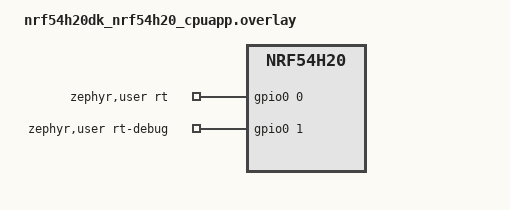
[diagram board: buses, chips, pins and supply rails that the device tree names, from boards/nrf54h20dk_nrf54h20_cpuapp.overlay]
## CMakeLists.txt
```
#
# Copyright (c) 2026 Nordic Semiconductor
#
# SPDX-License-Identifier: LicenseRef-Nordic-5-Clause
#

cmake_minimum_required(VERSION 3.20.0)
find_package(Zephyr REQUIRED HINTS $ENV{ZEPHYR_BASE})
project(rtfw_timer_gpio)

target_sources(app PRIVATE
  src/main.c
  src/timer_control.c
  src/timer_fastpath.c
)
```

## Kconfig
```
#
# Copyright (c) 2026 Nordic Semiconductor
#
# SPDX-License-Identifier: LicenseRef-Nordic-5-Clause
#

mainmenu "RTFW timer/GPIO backend"

config SAMPLE_RTFW_IRQ_PRIORITY
	int "TIMER zero-latency IRQ priority"
	default 1 if SOC_SERIES_NRF54L
	default 0
	range 0 7
	help
	  Select the priority of the sample-owned TIMER source interrupt.
	  nRF54L uses priority 1 so MPSL priority 0 can preempt it, while
	  nRF54H20 uses priority 0 because the radio runs on another core.

config SAMPLE_RTFW_TIMER_MIN_PERIOD_US
	int "Minimum accepted timer period (us)"
	default 10
	range 2 2147483647
	help
	  Set the shortest period accepted by the sample API. The TIMER runs at
	  1 MHz and requires at least two counter ticks. Values below this
	  limit are rejected instead of being silently rounded by the
	  zero-latency command handler.

config SAMPLE_RTFW_TIMER_MAX_PERIOD_US
	int "Maximum accepted timer period (us)"
	default 1000000
	range 2 2147483647
	help
	  Set the longest period accepted by the sample API. This value must be
	  greater than or equal to the configured minimum period. The default
	  sample period must remain within the resulting accepted range or the
	  build is rejected.

config SAMPLE_RTFW_TIMER_TELEMETRY_DECIMATION
	int "Emit one tick event every N timer events (0 disables)"
	default 0
	range 0 1000000
	help
	  Tick telemetry is disabled by default. Configuration changes remain
	  event-on-change and are not affected by this setting.

config SAMPLE_RTFW_ISR_TEST_LOAD
	bool "Inject a controlled busy loop into the TIMER fast path"
	help
	  Add a bounded NOP loop to the source ISR for stress and
	  coexistence measurements. The configured iteration count is
	  executed after the registered fast-path callback. Keep this
	  option disabled for baseline latency measurements.

config SAMPLE_RTFW_ISR_TEST_LOAD_CYCLES
	int "NOP iterations in the injected ISR load"
	depends on SAMPLE_RTFW_ISR_TEST_LOAD
	default 100
	range 1 1000000

config SAMPLE_RTFW_DEBUG_PIN
	bool "Expose TIMER ISR execution time on a debug pin"
	help
	  Drive the board-specific debug pin while the direct source ISR
	  executes so its latency and duration can be measured with a
	  logic analyzer. The output includes framework command handling
	  and the registered sample fast-path callback.

source "Kconfig.zephyr"
```

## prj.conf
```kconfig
#
# Copyright (c) 2026 Nordic Semiconductor
#
# SPDX-License-Identifier: LicenseRef-Nordic-5-Clause
#

CONFIG_NCS_SAMPLES_DEFAULTS=y
CONFIG_RTFW=y
CONFIG_RTFW_COMMAND_DATA_SIZE=8
CONFIG_ZERO_LATENCY_IRQS=y
CONFIG_ZERO_LATENCY_LEVELS=2

CONFIG_DK_LIBRARY=y

CONFIG_SHELL=y
CONFIG_SYSTEM_WORKQUEUE_STACK_SIZE=2048
```

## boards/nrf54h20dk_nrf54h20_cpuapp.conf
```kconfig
CONFIG_BT=n
CONFIG_ZERO_LATENCY_LEVELS=1
CONFIG_SAMPLE_RTFW_IRQ_PRIORITY=0
```

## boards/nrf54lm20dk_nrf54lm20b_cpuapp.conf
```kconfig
CONFIG_BT=y
CONFIG_BT_PERIPHERAL=y
CONFIG_BT_DEVICE_NAME="Nordic_RTFW_Timer"
CONFIG_BT_LBS=y
CONFIG_SAMPLE_RTFW_IRQ_PRIORITY=1
```

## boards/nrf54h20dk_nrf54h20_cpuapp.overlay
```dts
/*
 * Copyright (c) 2026 Nordic Semiconductor
 *
 * SPDX-License-Identifier: LicenseRef-Nordic-5-Clause
 */

#include <zephyr/dt-bindings/gpio/gpio.h>

/ {
	aliases {
		rt-timer = &timer130;
		rt-egu = &egu130;
	};

	zephyr,user {
		rt-gpios = <&gpio0 0 GPIO_ACTIVE_HIGH>;
		rt-debug-gpios = <&gpio0 1 GPIO_ACTIVE_HIGH>;
	};
};

&timer130 {
	status = "reserved";
};

&egu130 {
	status = "reserved";
};

&gpio0 {
	status = "okay";
};
```

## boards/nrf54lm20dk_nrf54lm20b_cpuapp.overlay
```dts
/*
 * Copyright (c) 2026 Nordic Semiconductor
 *
 * SPDX-License-Identifier: LicenseRef-Nordic-5-Clause
 */

#include <zephyr/dt-bindings/gpio/gpio.h>

/ {
	aliases {
		rt-timer = &timer20;
		rt-egu = &egu20;
	};

	zephyr,user {
		rt-gpios = <&gpio1 4 GPIO_ACTIVE_HIGH>;
		rt-debug-gpios = <&gpio1 5 GPIO_ACTIVE_HIGH>;
	};
};

&timer20 {
	status = "disabled";
};

&egu20 {
	status = "disabled";
};
```

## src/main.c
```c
/*
 * Copyright (c) 2026 Nordic Semiconductor
 *
 * SPDX-License-Identifier: LicenseRef-Nordic-5-Clause
 */

#include <errno.h>
#include <zephyr/kernel.h>
#include <zephyr/shell/shell.h>
#include <zephyr/sys/printk.h>
#include <dk_buttons_and_leds.h>

#if defined(CONFIG_BT)
#include <zephyr/bluetooth/bluetooth.h>
#include <zephyr/bluetooth/conn.h>
#include <zephyr/bluetooth/gatt.h>
#include <zephyr/bluetooth/hci.h>
#include <zephyr/bluetooth/uuid.h>
#include <bluetooth/services/lbs.h>
#endif

#include "timer_internal.h"

#define RUN_STATUS_LED         DK_LED1
#define CONNECTION_STATUS_LED  DK_LED2
#define EVENT_STATUS_LED       DK_LED3
#define RUN_LED_INTERVAL_MS    1000

#if defined(CONFIG_BT)
#define DEVICE_NAME     CONFIG_BT_DEVICE_NAME
#define DEVICE_NAME_LEN (sizeof(DEVICE_NAME) - 1)

static struct k_work advertising_work;

static const struct bt_data advertising_data[] = {
	BT_DATA_BYTES(BT_DATA_FLAGS, BT_LE_AD_GENERAL | BT_LE_AD_NO_BREDR),
	BT_DATA(BT_DATA_NAME_COMPLETE, DEVICE_NAME, DEVICE_NAME_LEN),
};

static const struct bt_data scan_data[] = {
	BT_DATA_BYTES(BT_DATA_UUID128_ALL, BT_UUID_LBS_VAL),
};

static void advertising_handler(struct k_work *work)
{
	int error;

	ARG_UNUSED(work);
	error = bt_le_adv_start(BT_LE_ADV_CONN_FAST_2, advertising_data,
				ARRAY_SIZE(advertising_data), scan_data,
				ARRAY_SIZE(scan_data));
	printk("Advertising start: %d\n", error);
}

static void connected(struct bt_conn *connection, uint8_t error)
{
	ARG_UNUSED(connection);
	if (error == 0U) {
		dk_set_led_on(CONNECTION_STATUS_LED);
	}
}

static void disconnected(struct bt_conn *connection, uint8_t reason)
{
	ARG_UNUSED(connection);
	ARG_UNUSED(reason);
	dk_set_led_off(CONNECTION_STATUS_LED);
}

static void recycled(void)
{
	k_work_submit(&advertising_work);
}

BT_CONN_CB_DEFINE(connection_callbacks) = {
	.connected = connected,
	.disconnected = disconnected,
	.recycled = recycled,
};

static struct bt_lbs_cb lbs_callbacks;
#endif

static bool event_led_state;

static void event_handler(const struct rtfw_event *event, void *user_data)
{
	ARG_UNUSED(user_data);

	if (event->type == RTFW_EVENT_COMMAND_PROCESSED ||
	    event->type == RTFW_TIMER_EVENT_TICK) {
		event_led_state = !event_led_state;
		dk_set_led(EVENT_STATUS_LED, event_led_state);
	}
}

static int command_start(const struct shell *shell, size_t argc, char **argv)
{
	ARG_UNUSED(argc);
	ARG_UNUSED(argv);
	int error = rtfw_timer_enable(true);

	shell_print(shell, "RTFW timer start requested (%d)", error);
	return error;
}

static int command_stop(const struct shell *shell, size_t argc, char **argv)
{
	ARG_UNUSED(argc);
	ARG_UNUSED(argv);
	int error = rtfw_timer_enable(false);

	shell_print(shell, "RTFW timer stop requested (%d)", error);
	return error;
}

static int command_period(const struct shell *shell, size_t argc, char **argv)
{
	int parse_error = 0;
	unsigned long period_us;
	int error;

	ARG_UNUSED(argc);
	period_us = shell_strtoul(argv[1], 0, &parse_error);
	if (parse_error != 0 ||
	    period_us > CONFIG_SAMPLE_RTFW_TIMER_MAX_PERIOD_US) {
		shell_error(shell, "Invalid period '%s'", argv[1]);
		return -EINVAL;
	}

	error = rtfw_timer_period_set((uint32_t)period_us);
	if (error != 0) {
		shell_error(shell, "Allowed range: %u..%u us",
			    CONFIG_SAMPLE_RTFW_TIMER_MIN_PERIOD_US,
			    CONFIG_SAMPLE_RTFW_TIMER_MAX_PERIOD_US);
		return error;
	}

	shell_print(shell, "RTFW timer period requested: %lu us", period_us);
	return 0;
}

static int command_status(const struct shell *shell, size_t argc, char **argv)
{
	struct rtfw_timer_status status;
	int error;

	ARG_UNUSED(argc);
	ARG_UNUSED(argv);
	error = rtfw_timer_status_get(&status);
	if (error != 0) {
		return error;
	}

	shell_print(shell, "applied   : %s, %u us (%u ticks)",
		    status.enabled ? "running" : "stopped",
		    status.period_us, status.period_ticks);
	shell_print(shell, "requested : %s, %u us (%u ticks)",
		    status.requested_enabled ? "running" : "stopped",
		    status.requested_period_us, status.requested_period_ticks);
	shell_print(shell, "pending=%s ticks=%u dropped=%u max_depth=%u faults=0x%x",
		    status.pending ? "yes" : "no", status.tick_count,
		    status.dropped_events, status.max_queue_depth, status.faults);
	return 0;
}

SHELL_STATIC_SUBCMD_SET_CREATE(rtfw_commands,
	SHELL_CMD(start, NULL, "Start the TIMER/GPIO backend", command_start),
	SHELL_CMD(stop, NULL, "Stop the TIMER/GPIO backend", command_stop),
	SHELL_CMD_ARG(period, NULL, "Set period in microseconds", command_period, 2, 0),
	SHELL_CMD(status, NULL, "Show coherent backend status", command_status),
	SHELL_SUBCMD_SET_END
);
SHELL_CMD_REGISTER(rtfw, &rtfw_commands, "RTFW timer/GPIO control", NULL);

int main(void)
{
	int error;
	bool led = false;

	printk("Starting event-driven RTFW timer/GPIO backend\n");
	error = dk_leds_init();
	if (error != 0) {
		return error;
	}

	error = rtfw_timer_init(event_handler, NULL);
	if (error != 0) {
		printk("RTFW initialization failed: %d\n", error);
		return error;
	}
#if defined(CONFIG_BT)
	error = bt_enable(NULL);
	if (error != 0) {
		return error;
	}
	error = bt_lbs_init(&lbs_callbacks);
	if (error != 0) {
		return error;
	}
	k_work_init(&advertising_work, advertising_handler);
	k_work_submit(&advertising_work);
#endif
	printk("RTFW timer/GPIO backend initialized\n");

	for (;;) {
		led = !led;
		dk_set_led(RUN_STATUS_LED, led);
		k_sleep(K_MSEC(RUN_LED_INTERVAL_MS));
	}
}
```

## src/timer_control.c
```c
/*
 * Copyright (c) 2026 Nordic Semiconductor
 *
 * SPDX-License-Identifier: LicenseRef-Nordic-5-Clause
 */

#include <errno.h>
#include <string.h>
#include <zephyr/kernel.h>

#include "timer_internal.h"

static K_MUTEX_DEFINE(timer_lock);
static struct rtfw_timer_config desired_config;
static uint32_t desired_period_us;

static int config_publish(const struct rtfw_timer_config *config)
{
	struct rtfw_command command = {
		.id = RTFW_TIMER_COMMAND_CONFIGURE,
		.data_len = sizeof(*config),
	};

	memcpy(command.data, config, sizeof(*config));
	return rtfw_submit(&command);
}

int rtfw_timer_init(rtfw_event_cb_t event_handler, void *user_data)
{
	const struct rtfw_config framework_config = {
		.command_handler = rtfw_timer_command_handler,
		.fastpath_handler = rtfw_timer_fastpath_handler,
		.pend_source_irq = rtfw_timer_pend_source_irq,
		.event_handler = event_handler,
		.event_user_data = user_data,
	};
	int error;

	desired_period_us = RTFW_TIMER_DEFAULT_PERIOD_US;
	desired_config.enabled = 0U;
	desired_config.period_ticks =
		rtfw_timer_us_to_ticks(RTFW_TIMER_DEFAULT_PERIOD_US);

	error = rtfw_init(&framework_config);
	if (error != 0) {
		return error;
	}

	rtfw_timer_fastpath_init(desired_config.period_ticks);
	return config_publish(&desired_config);
}

int rtfw_timer_enable(bool enable)
{
	struct rtfw_timer_config config;
	int error;

	k_mutex_lock(&timer_lock, K_FOREVER);
	config = desired_config;
	config.enabled = enable ? 1U : 0U;
	error = config_publish(&config);
	if (error == 0) {
		desired_config = config;
	}
	k_mutex_unlock(&timer_lock);
	return error;
}

int rtfw_timer_period_set(uint32_t period_us)
{
	struct rtfw_timer_config config;
	uint32_t period_ticks;
	int error;

	if (period_us < CONFIG_SAMPLE_RTFW_TIMER_MIN_PERIOD_US ||
	    period_us > CONFIG_SAMPLE_RTFW_TIMER_MAX_PERIOD_US) {
		return -EINVAL;
	}
	period_ticks = rtfw_timer_us_to_ticks(period_us);
	if (period_ticks < RTFW_TIMER_MIN_PERIOD_TICKS) {
		return -EINVAL;
	}

	k_mutex_lock(&timer_lock, K_FOREVER);
	config = desired_config;
	config.period_ticks = period_ticks;
	error = config_publish(&config);
	if (error == 0) {
		desired_config = config;
		desired_period_us = period_us;
	}
	k_mutex_unlock(&timer_lock);
	return error;
}

int rtfw_timer_status_get(struct rtfw_timer_status *status)
{
	struct rtfw_status framework_status;
	struct rtfw_timer_config applied = {0};
	bool applied_valid;
	int error;

	if (status == NULL) {
		return -EINVAL;
	}

	k_mutex_lock(&timer_lock, K_FOREVER);
	error = rtfw_get_status(&framework_status);
	if (error != 0) {
		k_mutex_unlock(&timer_lock);
		return error;
	}

	status->requested_enabled = desired_config.enabled != 0U;
	status->requested_period_us = desired_period_us;
	status->requested_period_ticks = desired_config.period_ticks;

	applied_valid =
		framework_status.applied.id == RTFW_TIMER_COMMAND_CONFIGURE &&
		framework_status.applied.data_len == sizeof(applied);
	if (applied_valid) {
		memcpy(&applied, framework_status.applied.data,
		       sizeof(applied));
	}
	status->enabled =
		applied_valid && applied.enabled != 0U;
	status->period_ticks = applied_valid ? applied.period_ticks :
					      desired_config.period_ticks;
	status->period_us = rtfw_timer_ticks_to_us(status->period_ticks);
	status->pending = framework_status.pending;
	status->tick_count = rtfw_timer_tick_count_get();
	status->dropped_events = framework_status.dropped_events;
	status->max_queue_depth = framework_status.max_queue_depth;
	status->faults = framework_status.faults;
	k_mutex_unlock(&timer_lock);
	return 0;
}
```

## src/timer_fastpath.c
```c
/*
 * Copyright (c) 2026 Nordic Semiconductor
 *
 * SPDX-License-Identifier: LicenseRef-Nordic-5-Clause
 */

#include <errno.h>
#include <limits.h>
#include <string.h>
#include <cmsis_core.h>
#include <zephyr/irq.h>
#include <hal/nrf_gpio.h>
#include <hal/nrf_timer.h>

#include "timer_internal.h"
#include "timer_platform.h"

#define TIMER_TARGET_HZ 1000000U

static struct rtfw_timer_config applied_config;
static uint8_t timer_prescaler;
static uint32_t timer_hz;
static uint32_t tick_count;

static void timer_clock_resolve(void)
{
	uint32_t base_hz;
	uint8_t prescaler = 0U;

	if (timer_hz != 0U) {
		return;
	}

	base_hz = NRF_TIMER_BASE_FREQUENCY_GET(RTFW_TIMER);
	while (((base_hz >> prescaler) > TIMER_TARGET_HZ) && (prescaler < 9U)) {
		prescaler++;
	}

	timer_prescaler = prescaler;
	timer_hz = base_hz >> prescaler;
}

int rtfw_timer_command_handler(const struct rtfw_command *command,
			       void *user_data)
{
	struct rtfw_timer_config config;
	uint32_t ticks;

	ARG_UNUSED(user_data);
	if (command->id != RTFW_TIMER_COMMAND_CONFIGURE ||
	    command->data_len != sizeof(struct rtfw_timer_config)) {
		return -EINVAL;
	}

	memcpy(&config, command->data, sizeof(config));
	if (config.period_ticks < RTFW_TIMER_MIN_PERIOD_TICKS) {
		return -EINVAL;
	}
	ticks = config.period_ticks;

	/*
	 * A reconfiguration intentionally starts a new phase. STOP/CLEAR before
	 * changing CC0 prevents a smaller compare value from being stranded below
	 * the current counter until the 32-bit counter wraps.
	 */
	nrf_timer_task_trigger(RTFW_TIMER, NRF_TIMER_TASK_STOP);
	nrf_timer_task_trigger(RTFW_TIMER, NRF_TIMER_TASK_CLEAR);
	nrf_timer_event_clear(RTFW_TIMER, NRF_TIMER_EVENT_COMPARE0);
	nrf_timer_cc_set(RTFW_TIMER, NRF_TIMER_CC_CHANNEL0, ticks);

	applied_config.enabled = config.enabled != 0U;
	applied_config.period_ticks = ticks;
	if (applied_config.enabled != 0U) {
		nrf_timer_task_trigger(RTFW_TIMER, NRF_TIMER_TASK_START);
	} else {
		nrf_gpio_pin_clear(RTFW_GPIO_ABS);
	}

	return 0;
}

void rtfw_timer_pend_source_irq(void *user_data)
{
	ARG_UNUSED(user_data);
	NVIC_SetPendingIRQ(RTFW_TIMER_IRQN);
}

void rtfw_timer_fastpath_handler(void *user_data)
{
	bool timer_event =
		nrf_timer_event_check(RTFW_TIMER, NRF_TIMER_EVENT_COMPARE0);

	ARG_UNUSED(user_data);
	if (timer_event) {
		nrf_timer_event_clear(RTFW_TIMER, NRF_TIMER_EVENT_COMPARE0);
	}

	if (timer_event && applied_config.enabled != 0U) {
		struct rtfw_event event;
		uint32_t current_tick;

		nrf_gpio_pin_toggle(RTFW_GPIO_ABS);
		current_tick = __atomic_add_fetch(&tick_count, 1U, __ATOMIC_RELAXED);

#if CONFIG_SAMPLE_RTFW_TIMER_TELEMETRY_DECIMATION > 0
		if ((current_tick %
		     CONFIG_SAMPLE_RTFW_TIMER_TELEMETRY_DECIMATION) == 0U) {
			event.type = RTFW_TIMER_EVENT_TICK;
			event.value = current_tick;
			event.timestamp = current_tick;
			(void)rtfw_event_push(&event);
		}
#else
		(void)event;
#endif
	}
}

ISR_DIRECT_DECLARE(rtfw_timer_isr)
{
#if defined(CONFIG_SAMPLE_RTFW_DEBUG_PIN)
	nrf_gpio_pin_set(RTFW_DEBUG_GPIO_ABS);
#endif

	rtfw_fastpath_run();

#if defined(CONFIG_SAMPLE_RTFW_ISR_TEST_LOAD)
	for (uint32_t i = 0U;
	     i < CONFIG_SAMPLE_RTFW_ISR_TEST_LOAD_CYCLES; i++) {
		__NOP();
	}
#endif

#if defined(CONFIG_SAMPLE_RTFW_DEBUG_PIN)
	nrf_gpio_pin_clear(RTFW_DEBUG_GPIO_ABS);
#endif

	return 0;
}

uint32_t rtfw_timer_us_to_ticks(uint32_t microseconds)
{
	uint64_t ticks;

	timer_clock_resolve();
	ticks = ((uint64_t)microseconds * timer_hz) / 1000000ULL;
	return (uint32_t)MIN(ticks, UINT32_MAX);
}

uint32_t rtfw_timer_ticks_to_us(uint32_t ticks)
{
	uint64_t microseconds;

	timer_clock_resolve();
	microseconds = ((uint64_t)ticks * 1000000ULL) / timer_hz;
	return (uint32_t)MIN(microseconds, UINT32_MAX);
}

uint32_t rtfw_timer_tick_count_get(void)
{
	return __atomic_load_n(&tick_count, __ATOMIC_RELAXED);
}

void rtfw_timer_fastpath_init(uint32_t initial_period_ticks)
{
	timer_clock_resolve();
	applied_config.enabled = 0U;
	applied_config.period_ticks = initial_period_ticks;
	__atomic_store_n(&tick_count, 0U, __ATOMIC_RELAXED);

	nrf_gpio_cfg_output(RTFW_GPIO_ABS);
	nrf_gpio_pin_clear(RTFW_GPIO_ABS);
#if defined(CONFIG_SAMPLE_RTFW_DEBUG_PIN)
	nrf_gpio_cfg_output(RTFW_DEBUG_GPIO_ABS);
	nrf_gpio_pin_clear(RTFW_DEBUG_GPIO_ABS);
#endif

	nrf_timer_task_trigger(RTFW_TIMER, NRF_TIMER_TASK_STOP);
	nrf_timer_task_trigger(RTFW_TIMER, NRF_TIMER_TASK_CLEAR);
	nrf_timer_mode_set(RTFW_TIMER, NRF_TIMER_MODE_TIMER);
	nrf_timer_bit_width_set(RTFW_TIMER, NRF_TIMER_BIT_WIDTH_32);
	nrf_timer_prescaler_set(RTFW_TIMER, timer_prescaler);
	nrf_timer_cc_set(RTFW_TIMER, NRF_TIMER_CC_CHANNEL0, initial_period_ticks);
	nrf_timer_shorts_enable(RTFW_TIMER, NRF_TIMER_SHORT_COMPARE0_CLEAR_MASK);
	nrf_timer_event_clear(RTFW_TIMER, NRF_TIMER_EVENT_COMPARE0);
	nrf_timer_int_enable(RTFW_TIMER, NRF_TIMER_INT_COMPARE0_MASK);

	IRQ_DIRECT_CONNECT(RTFW_TIMER_IRQN, CONFIG_SAMPLE_RTFW_IRQ_PRIORITY,
			   rtfw_timer_isr, IRQ_ZERO_LATENCY);
	irq_enable(RTFW_TIMER_IRQN);
}
```

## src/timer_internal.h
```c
/*
 * Copyright (c) 2026 Nordic Semiconductor
 *
 * SPDX-License-Identifier: LicenseRef-Nordic-5-Clause
 */

#ifndef RTFW_TIMER_INTERNAL_H_
#define RTFW_TIMER_INTERNAL_H_

#include <stdbool.h>
#include <stdint.h>
#include <zephyr/sys/util.h>
#include <rtfw/rtfw.h>

#define RTFW_TIMER_COMMAND_CONFIGURE 1U
#define RTFW_TIMER_EVENT_TICK        RTFW_EVENT_TYPE_USER_BASE
#define RTFW_TIMER_DEFAULT_PERIOD_US 500000U
#define RTFW_TIMER_MIN_PERIOD_TICKS  2U

struct rtfw_timer_config {
	uint32_t enabled;
	uint32_t period_ticks;
};

BUILD_ASSERT(sizeof(struct rtfw_timer_config) <=
	     CONFIG_RTFW_COMMAND_DATA_SIZE,
	     "RTFW command payload is too small for the TIMER configuration");
BUILD_ASSERT(CONFIG_SAMPLE_RTFW_TIMER_MIN_PERIOD_US <=
	     CONFIG_SAMPLE_RTFW_TIMER_MAX_PERIOD_US,
	     "minimum TIMER period must not exceed maximum");
BUILD_ASSERT(RTFW_TIMER_DEFAULT_PERIOD_US >=
	     CONFIG_SAMPLE_RTFW_TIMER_MIN_PERIOD_US &&
	     RTFW_TIMER_DEFAULT_PERIOD_US <=
	     CONFIG_SAMPLE_RTFW_TIMER_MAX_PERIOD_US,
	     "default TIMER period must be inside the accepted range");

struct rtfw_timer_status {
	bool enabled;
	uint32_t period_us;
	uint32_t period_ticks;
	bool requested_enabled;
	uint32_t requested_period_us;
	uint32_t requested_period_ticks;
	bool pending;
	uint32_t tick_count;
	uint32_t dropped_events;
	uint32_t max_queue_depth;
	uint32_t faults;
};

int rtfw_timer_init(rtfw_event_cb_t event_handler, void *user_data);
int rtfw_timer_enable(bool enable);
int rtfw_timer_period_set(uint32_t period_us);
int rtfw_timer_status_get(struct rtfw_timer_status *status);

int rtfw_timer_command_handler(const struct rtfw_command *command,
			       void *user_data);
void rtfw_timer_fastpath_handler(void *user_data);
void rtfw_timer_pend_source_irq(void *user_data);
void rtfw_timer_fastpath_init(uint32_t initial_period_ticks);
uint32_t rtfw_timer_us_to_ticks(uint32_t microseconds);
uint32_t rtfw_timer_ticks_to_us(uint32_t ticks);
uint32_t rtfw_timer_tick_count_get(void);

#endif /* RTFW_TIMER_INTERNAL_H_ */
```

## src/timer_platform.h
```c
/*
 * Copyright (c) 2026 Nordic Semiconductor
 *
 * SPDX-License-Identifier: LicenseRef-Nordic-5-Clause
 */

#ifndef RTFW_TIMER_PLATFORM_H_
#define RTFW_TIMER_PLATFORM_H_

#include <zephyr/devicetree.h>
#include <zephyr/dt-bindings/gpio/gpio.h>
#include <zephyr/irq.h>
#include <soc.h>
#include <hal/nrf_timer.h>

#define RTFW_TIMER_NODE DT_ALIAS(rt_timer)
#define RTFW_USER_NODE  DT_PATH(zephyr_user)

BUILD_ASSERT(DT_NODE_EXISTS(RTFW_TIMER_NODE),
	     "timer/GPIO backend requires the rt-timer alias");
BUILD_ASSERT(CONFIG_SAMPLE_RTFW_IRQ_PRIORITY < ZERO_LATENCY_LEVELS,
	     "RTFW priority must be inside the zero-latency priority range");
BUILD_ASSERT(!IS_ENABLED(CONFIG_PM),
	     "timer/GPIO sample does not support system PM");
#if defined(CONFIG_SOC_SERIES_NRF54L)
BUILD_ASSERT(CONFIG_SAMPLE_RTFW_IRQ_PRIORITY == 1,
	     "nRF54L RTFW must leave priority 0 to MPSL");
#else
BUILD_ASSERT(CONFIG_SAMPLE_RTFW_IRQ_PRIORITY == 0,
	     "nRF54H20 app-core RTFW must use priority 0");
#endif

#define RTFW_TIMER      ((NRF_TIMER_Type *)DT_REG_ADDR(RTFW_TIMER_NODE))
#define RTFW_TIMER_IRQN DT_IRQN(RTFW_TIMER_NODE)
#define RTFW_GPIO_ABS   NRF_DT_GPIOS_TO_PSEL(RTFW_USER_NODE, rt_gpios)

BUILD_ASSERT((DT_GPIO_FLAGS(RTFW_USER_NODE, rt_gpios) & GPIO_ACTIVE_LOW) == 0,
	     "rt-gpios must be active-high");

#if defined(CONFIG_SAMPLE_RTFW_DEBUG_PIN)
#define RTFW_DEBUG_GPIO_ABS NRF_DT_GPIOS_TO_PSEL(RTFW_USER_NODE, rt_debug_gpios)
BUILD_ASSERT((DT_GPIO_FLAGS(RTFW_USER_NODE, rt_debug_gpios) & GPIO_ACTIVE_LOW) == 0,
	     "rt-debug-gpios must be active-high");
#endif

#endif /* RTFW_TIMER_PLATFORM_H_ */
```
